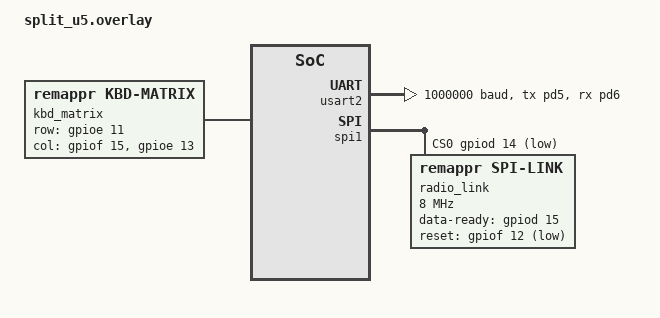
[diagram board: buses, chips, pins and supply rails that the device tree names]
/*
 * Split U5 — Remappr shield (generated by remappr).
 *
 * Drop this directory into a remappr-firmware checkout under
 * boards/shields/split_u5/ and build with -DSHIELD=split_u5. Verify the
 * row/col GPIO specs against your wiring — remappr derives the matrix
 * cells from physical key position, not the electrical matrix.
 *
 * SPDX-License-Identifier: Apache-2.0
 */

#include <zephyr/dt-bindings/input/input-event-codes.h>
#include <zephyr/dt-bindings/input/keymap.h>
#include <dt-bindings/remappr/keys.h>
#include <dt-bindings/remappr/layout.h>
#include <remappr/keymap-tokens.dtsi>
#include <remappr/behavior-tokens.dtsi>
#include <zephyr/dt-bindings/dma/stm32_dma.h>

/ {
	kbd_matrix: kbd-matrix {
		compatible = "remappr,kbd-matrix";
		diode-direction = "row2col";
		row-gpios =
			<&gpioe 11 GPIO_ACTIVE_HIGH>;
		col-gpios =
			<&gpiof 15 (GPIO_ACTIVE_HIGH | GPIO_PULL_DOWN)>,
			<&gpioe 13 (GPIO_ACTIVE_HIGH | GPIO_PULL_DOWN)>;

		keymap {
			compatible = "input-keymap";
			keymap = <
				MATRIX_KEY(0, 0, REMAPPR_KB_POS_BASE + 0) MATRIX_KEY(0, 1, REMAPPR_KB_POS_BASE + 1)
			>;
			row-size = <1>;
			col-size = <2>;
		};
	};

	remappr_keymap: remappr-keymap {
		compatible = "remappr,keymap";
		scan = <&kbd_matrix>;
		columns = <2>;
		rows = <2>;
		max-layers = <4>;
		placement = <
				KEY(&x 0 &y 0) KEY(&x 1 &y 0)
		>;
		layer_0 {
			compatible = "remappr,keymap-layer";
			index = <0>;
			actions = <
				&key 0x04 &key 0x05
			>;
		};
	};
};

&gpdma1 {
	status = "okay";
};

&usart2 {
	pinctrl-0 = <&usart2_tx_pd5 &usart2_rx_pd6>;
	pinctrl-names = "default";
	current-speed = <1000000>;
	dmas = <&gpdma1 2 27 STM32_DMA_PERIPH_TX>, <&gpdma1 3 26 STM32_DMA_PERIPH_RX>;
	dma-names = "tx", "rx";
	status = "okay";
};

/ {
	node_bus_0: node_bus_0 {
		compatible = "remappr,node-bus-port";
		uart = <&usart2>;
		direction = "downstream";
		label = "dn";
	};
};

&spi1 {
	status = "okay";
	cs-gpios = <&gpiod 14 GPIO_ACTIVE_LOW>;

	radio_link: radio-link@0 {
		compatible = "remappr,spi-link";
		reg = <0>;
		spi-max-frequency = <8000000>;
		data-ready-gpios = <&gpiod 15 GPIO_ACTIVE_HIGH>;
		reset-gpios = <&gpiof 12 (GPIO_ACTIVE_LOW | GPIO_PULL_UP)>;
	};
};

/ {
	radio_config: radio-config {
		compatible = "remappr,radio-config";
		/* RF channels 2, 26, 50, 74, 98, 14, 38, 62, 86 */
		channel-seed = [02 1a 32 4a 62 0e 26 3e 56];
	};
};
